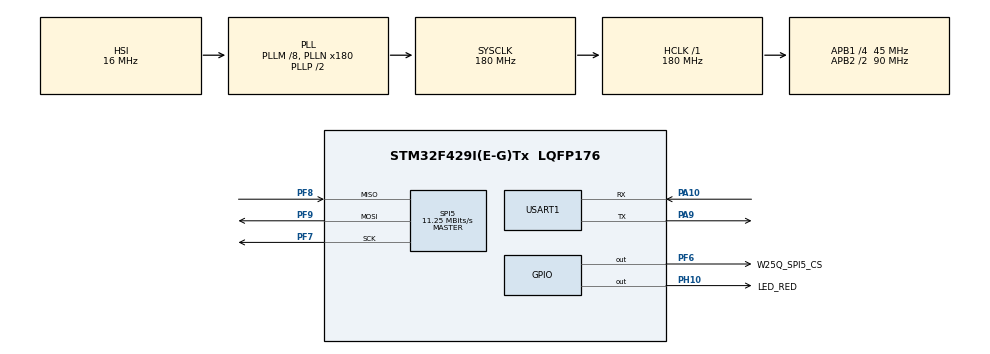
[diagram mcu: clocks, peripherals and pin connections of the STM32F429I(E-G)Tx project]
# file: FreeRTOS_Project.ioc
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Dma.Request0=USART1_RX
Dma.Request1=USART1_TX
Dma.Request2=SPI5_RX
Dma.Request3=SPI5_TX
Dma.SPI5_RX.2.Direction=DMA_PERIPH_TO_MEMORY
Dma.SPI5_RX.2.FIFOMode=DMA_FIFOMODE_DISABLE
Dma.SPI5_RX.2.Instance=DMA2_Stream3
Dma.SPI5_RX.2.MemDataAlignment=DMA_MDATAALIGN_BYTE
Dma.SPI5_RX.2.MemInc=DMA_MINC_ENABLE
Dma.SPI5_RX.2.Mode=DMA_NORMAL
Dma.SPI5_RX.2.PeriphDataAlignment=DMA_PDATAALIGN_BYTE
Dma.SPI5_RX.2.PeriphInc=DMA_PINC_DISABLE
Dma.SPI5_RX.2.Priority=DMA_PRIORITY_LOW
Dma.SPI5_TX.3.Direction=DMA_MEMORY_TO_PERIPH
Dma.SPI5_TX.3.FIFOMode=DMA_FIFOMODE_DISABLE
Dma.SPI5_TX.3.Instance=DMA2_Stream4
Dma.SPI5_TX.3.MemDataAlignment=DMA_MDATAALIGN_BYTE
Dma.SPI5_TX.3.MemInc=DMA_MINC_ENABLE
Dma.SPI5_TX.3.Mode=DMA_NORMAL
Dma.SPI5_TX.3.PeriphDataAlignment=DMA_PDATAALIGN_BYTE
Dma.SPI5_TX.3.PeriphInc=DMA_PINC_DISABLE
Dma.SPI5_TX.3.Priority=DMA_PRIORITY_LOW
Dma.USART1_RX.0.Direction=DMA_PERIPH_TO_MEMORY
Dma.USART1_RX.0.FIFOMode=DMA_FIFOMODE_DISABLE
Dma.USART1_RX.0.Instance=DMA2_Stream2
Dma.USART1_RX.0.MemDataAlignment=DMA_MDATAALIGN_BYTE
Dma.USART1_RX.0.MemInc=DMA_MINC_ENABLE
Dma.USART1_RX.0.Mode=DMA_NORMAL
Dma.USART1_RX.0.PeriphDataAlignment=DMA_PDATAALIGN_BYTE
Dma.USART1_RX.0.PeriphInc=DMA_PINC_DISABLE
Dma.USART1_RX.0.Priority=DMA_PRIORITY_LOW
Dma.USART1_TX.1.Direction=DMA_MEMORY_TO_PERIPH
Dma.USART1_TX.1.FIFOMode=DMA_FIFOMODE_DISABLE
Dma.USART1_TX.1.Instance=DMA2_Stream7
Dma.USART1_TX.1.MemDataAlignment=DMA_MDATAALIGN_BYTE
Dma.USART1_TX.1.MemInc=DMA_MINC_ENABLE
Dma.USART1_TX.1.Mode=DMA_NORMAL
Dma.USART1_TX.1.PeriphDataAlignment=DMA_PDATAALIGN_BYTE
Dma.USART1_TX.1.PeriphInc=DMA_PINC_DISABLE
Dma.USART1_TX.1.Priority=DMA_PRIORITY_LOW
FREERTOS.Tasks01=defaultTask,0,128,StartDefaultTask,Default,NULL,Dynamic,NULL,NULL
FREERTOS.configENABLE_FPU=1
Mcu.Family=STM32F4
Mcu.Name=STM32F429I(E-G)Tx
Mcu.Package=LQFP176
Mcu.UserConstants=PRINT_COM,$$_USART1_IP_HANDLE_$$;W25Q_COM,$$_SPI5_IP_HANDLE_$$
NVIC.DMA2_Stream2_IRQn=true\:5\:0\:false\:false\:true\:true\:false\:true\:true
NVIC.DMA2_Stream3_IRQn=true\:5\:0\:false\:false\:true\:true\:false\:true\:true
NVIC.DMA2_Stream4_IRQn=true\:5\:0\:false\:false\:true\:true\:false\:true\:true
NVIC.DMA2_Stream7_IRQn=true\:5\:0\:false\:false\:true\:true\:false\:true\:true
NVIC.PriorityGroup=NVIC_PRIORITYGROUP_4
NVIC.SPI5_IRQn=true\:5\:0\:false\:false\:true\:true\:true\:true\:true
NVIC.USART1_IRQn=true\:5\:0\:false\:false\:true\:true\:true\:true\:true
PA10.Mode=Asynchronous
PA10.Signal=USART1_RX
PA9.Mode=Asynchronous
PA9.Signal=USART1_TX
PF6.GPIO_Label=W25Q_SPI5_CS
PF6.GPIO_PuPd=GPIO_PULLUP
PF6.GPIO_Speed=GPIO_SPEED_FREQ_VERY_HIGH
PF6.PinState=GPIO_PIN_SET
PF6.Signal=GPIO_Output
PF7.Mode=Full_Duplex_Master
PF7.Signal=SPI5_SCK
PF8.Mode=Full_Duplex_Master
PF8.Signal=SPI5_MISO
PF9.Mode=Full_Duplex_Master
PF9.Signal=SPI5_MOSI
PH0/OSC_IN.Mode=HSE-External-Oscillator
PH0/OSC_IN.Signal=RCC_OSC_IN
PH1/OSC_OUT.Mode=HSE-External-Oscillator
PH1/OSC_OUT.Signal=RCC_OSC_OUT
PH10.GPIO_Label=LED_RED
PH10.Signal=GPIO_Output
ProjectManager.HeapSize=0x200
ProjectManager.StackSize=0x400
ProjectManager.TargetToolchain=STM32CubeIDE
RCC.48MHZClocksFreq_Value=90000000
RCC.AHBFreq_Value=180000000
RCC.APB1CLKDivider=RCC_HCLK_DIV4
RCC.APB1Freq_Value=45000000
RCC.APB1TimFreq_Value=90000000
RCC.APB2CLKDivider=RCC_HCLK_DIV2
RCC.APB2Freq_Value=90000000
RCC.APB2TimFreq_Value=180000000
RCC.CortexFreq_Value=180000000
RCC.HCLKFreq_Value=180000000
RCC.HSE_VALUE=25000000
RCC.HSI_VALUE=16000000
RCC.LSE_VALUE=32768
RCC.PLLM=8
RCC.PLLN=180
RCC.SYSCLKFreq_VALUE=180000000
RCC.SYSCLKSource=RCC_SYSCLKSOURCE_PLLCLK
RCC.VCOOutputFreq_Value=360000000
SPI5.BaudRatePrescaler=SPI_BAUDRATEPRESCALER_8
SPI5.CLKPhase=SPI_PHASE_2EDGE
SPI5.CLKPolarity=SPI_POLARITY_HIGH
SPI5.CRCCalculation=SPI_CRCCALCULATION_DISABLE
SPI5.CalculateBaudRate=11.25 MBits/s
SPI5.Direction=SPI_DIRECTION_2LINES
SPI5.Mode=SPI_MODE_MASTER
SPI5.VirtualType=VM_MASTER
USART1.VirtualMode=VM_ASYNC
VP_FREERTOS_VS_CMSIS_V1.Mode=CMSIS_V1
board=custom

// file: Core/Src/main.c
/* USER CODE BEGIN Header */
/**
  ******************************************************************************
  * @file           : main.c
  * @brief          : Main program body
  ******************************************************************************
  * @attention
  *
  * Copyright (c) 2025 STMicroelectronics.
  * All rights reserved.
  *
  * This software is licensed under terms that can be found in the LICENSE file
  * in the root directory of this software component.
  * If no LICENSE file comes with this software, it is provided AS-IS.
  *
  ******************************************************************************
  */
/* USER CODE END Header */
#include "main.h"
#include "cmsis_os.h"
#include "dma.h"
#include "spi.h"
#include "usart.h"
#include "gpio.h"

void SystemClock_Config(void);
void MX_FREERTOS_Init(void);

int main(void)
{

  /* MCU Configuration--------------------------------------------------------*/

  /* Reset of all peripherals, Initializes the Flash interface and the Systick. */
  HAL_Init();

  /* Configure the system clock */
  SystemClock_Config();

  /* Initialize all configured peripherals */
  MX_GPIO_Init();
  MX_DMA_Init();
  MX_USART1_UART_Init();
  MX_SPI5_Init();

  /* Call init function for freertos objects (in cmsis_os2.c) */
  MX_FREERTOS_Init();

  /* Start scheduler */
  osKernelStart();

  /* We should never get here as control is now taken by the scheduler */

  /* Infinite loop */
  while (1)
  {

  }
}

void SystemClock_Config(void)
{
  RCC_OscInitTypeDef RCC_OscInitStruct = {0};
  RCC_ClkInitTypeDef RCC_ClkInitStruct = {0};

  /** Configure the main internal regulator output voltage
  */
  __HAL_RCC_PWR_CLK_ENABLE();
  __HAL_PWR_VOLTAGESCALING_CONFIG(PWR_REGULATOR_VOLTAGE_SCALE1);

  /** Initializes the RCC Oscillators according to the specified parameters
  * in the RCC_OscInitTypeDef structure.
  */
  RCC_OscInitStruct.OscillatorType = RCC_OSCILLATORTYPE_HSI;
  RCC_OscInitStruct.HSIState = RCC_HSI_ON;
  RCC_OscInitStruct.HSICalibrationValue = RCC_HSICALIBRATION_DEFAULT;
  RCC_OscInitStruct.PLL.PLLState = RCC_PLL_ON;
  RCC_OscInitStruct.PLL.PLLSource = RCC_PLLSOURCE_HSI;
  RCC_OscInitStruct.PLL.PLLM = 8;
  RCC_OscInitStruct.PLL.PLLN = 180;
  RCC_OscInitStruct.PLL.PLLP = RCC_PLLP_DIV2;
  RCC_OscInitStruct.PLL.PLLQ = 4;
  if (HAL_RCC_OscConfig(&RCC_OscInitStruct) != HAL_OK)
  {
    Error_Handler();
  }

  /** Activate the Over-Drive mode
  */
  if (HAL_PWREx_EnableOverDrive() != HAL_OK)
  {
    Error_Handler();
  }

  /** Initializes the CPU, AHB and APB buses clocks
  */
  RCC_ClkInitStruct.ClockType = RCC_CLOCKTYPE_HCLK|RCC_CLOCKTYPE_SYSCLK
                              |RCC_CLOCKTYPE_PCLK1|RCC_CLOCKTYPE_PCLK2;
  RCC_ClkInitStruct.SYSCLKSource = RCC_SYSCLKSOURCE_PLLCLK;
  RCC_ClkInitStruct.AHBCLKDivider = RCC_SYSCLK_DIV1;
  RCC_ClkInitStruct.APB1CLKDivider = RCC_HCLK_DIV4;
  RCC_ClkInitStruct.APB2CLKDivider = RCC_HCLK_DIV2;

  if (HAL_RCC_ClockConfig(&RCC_ClkInitStruct, FLASH_LATENCY_5) != HAL_OK)
  {
    Error_Handler();
  }
}

void Error_Handler(void)
{
  __disable_irq();
  while (1)
  {
  }
}

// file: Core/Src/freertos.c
/* USER CODE BEGIN Header */
/**
  ******************************************************************************
  * File Name          : freertos.c
  * Description        : Code for freertos applications
  ******************************************************************************
  * @attention
  *
  * Copyright (c) 2025 STMicroelectronics.
  * All rights reserved.
  *
  * This software is licensed under terms that can be found in the LICENSE file
  * in the root directory of this software component.
  * If no LICENSE file comes with this software, it is provided AS-IS.
  *
  ******************************************************************************
  */
/* USER CODE END Header */

#include "FreeRTOS.h"
#include "task.h"
#include "main.h"
#include "cmsis_os.h"

/* USER CODE BEGIN Includes */
#include "user_task.h"
/* USER CODE END Includes */

/* USER CODE BEGIN Variables */
osThreadId user50msTask;
osThreadId user100msTask;
osThreadId user1000msTask;
/* USER CODE END Variables */
osThreadId defaultTaskHandle;

void StartDefaultTask(void const * argument);

void MX_FREERTOS_Init(void); /* (MISRA C 2004 rule 8.1) */

/* GetIdleTaskMemory prototype (linked to static allocation support) */
void vApplicationGetIdleTaskMemory( StaticTask_t **ppxIdleTaskTCBBuffer, StackType_t **ppxIdleTaskStackBuffer, uint32_t *pulIdleTaskStackSize );

/* USER CODE BEGIN GET_IDLE_TASK_MEMORY */
static StaticTask_t xIdleTaskTCBBuffer;
static StackType_t xIdleStack[configMINIMAL_STACK_SIZE];

void vApplicationGetIdleTaskMemory( StaticTask_t **ppxIdleTaskTCBBuffer, StackType_t **ppxIdleTaskStackBuffer, uint32_t *pulIdleTaskStackSize )
{
  *ppxIdleTaskTCBBuffer = &xIdleTaskTCBBuffer;
  *ppxIdleTaskStackBuffer = &xIdleStack[0];
  *pulIdleTaskStackSize = configMINIMAL_STACK_SIZE;
  /* place for user code */
}
/* USER CODE END GET_IDLE_TASK_MEMORY */

void MX_FREERTOS_Init(void) {
  /* USER CODE BEGIN Init */
  Led_Init();
  Log_Init();
  SPI_FLASH_Init();
  /* USER CODE END Init */

  /* Create the thread(s) */
  /* definition and creation of defaultTask */
  osThreadDef(defaultTask, StartDefaultTask, osPriorityNormal, 0, 128);
  defaultTaskHandle = osThreadCreate(osThread(defaultTask), NULL);

  /* USER CODE BEGIN RTOS_THREADS */
  osThreadDef(TASK100MS_NAME, Task100ms, TASK100MS_PRIORITY, 0, TASK100MS_STACK_SIZE);
  defaultTaskHandle = osThreadCreate(osThread(TASK100MS_NAME), NULL);

  osThreadDef(TASK1000MS_NAME, Task1000ms, TASK1000MS_PRIORITY, 0, TASK1000MS_STACK_SIZE);
  defaultTaskHandle = osThreadCreate(osThread(TASK1000MS_NAME), NULL);
  /* USER CODE END RTOS_THREADS */

}

void StartDefaultTask(void const * argument)
{
  for(;;)
  {
    osDelay(1);
  }
}
